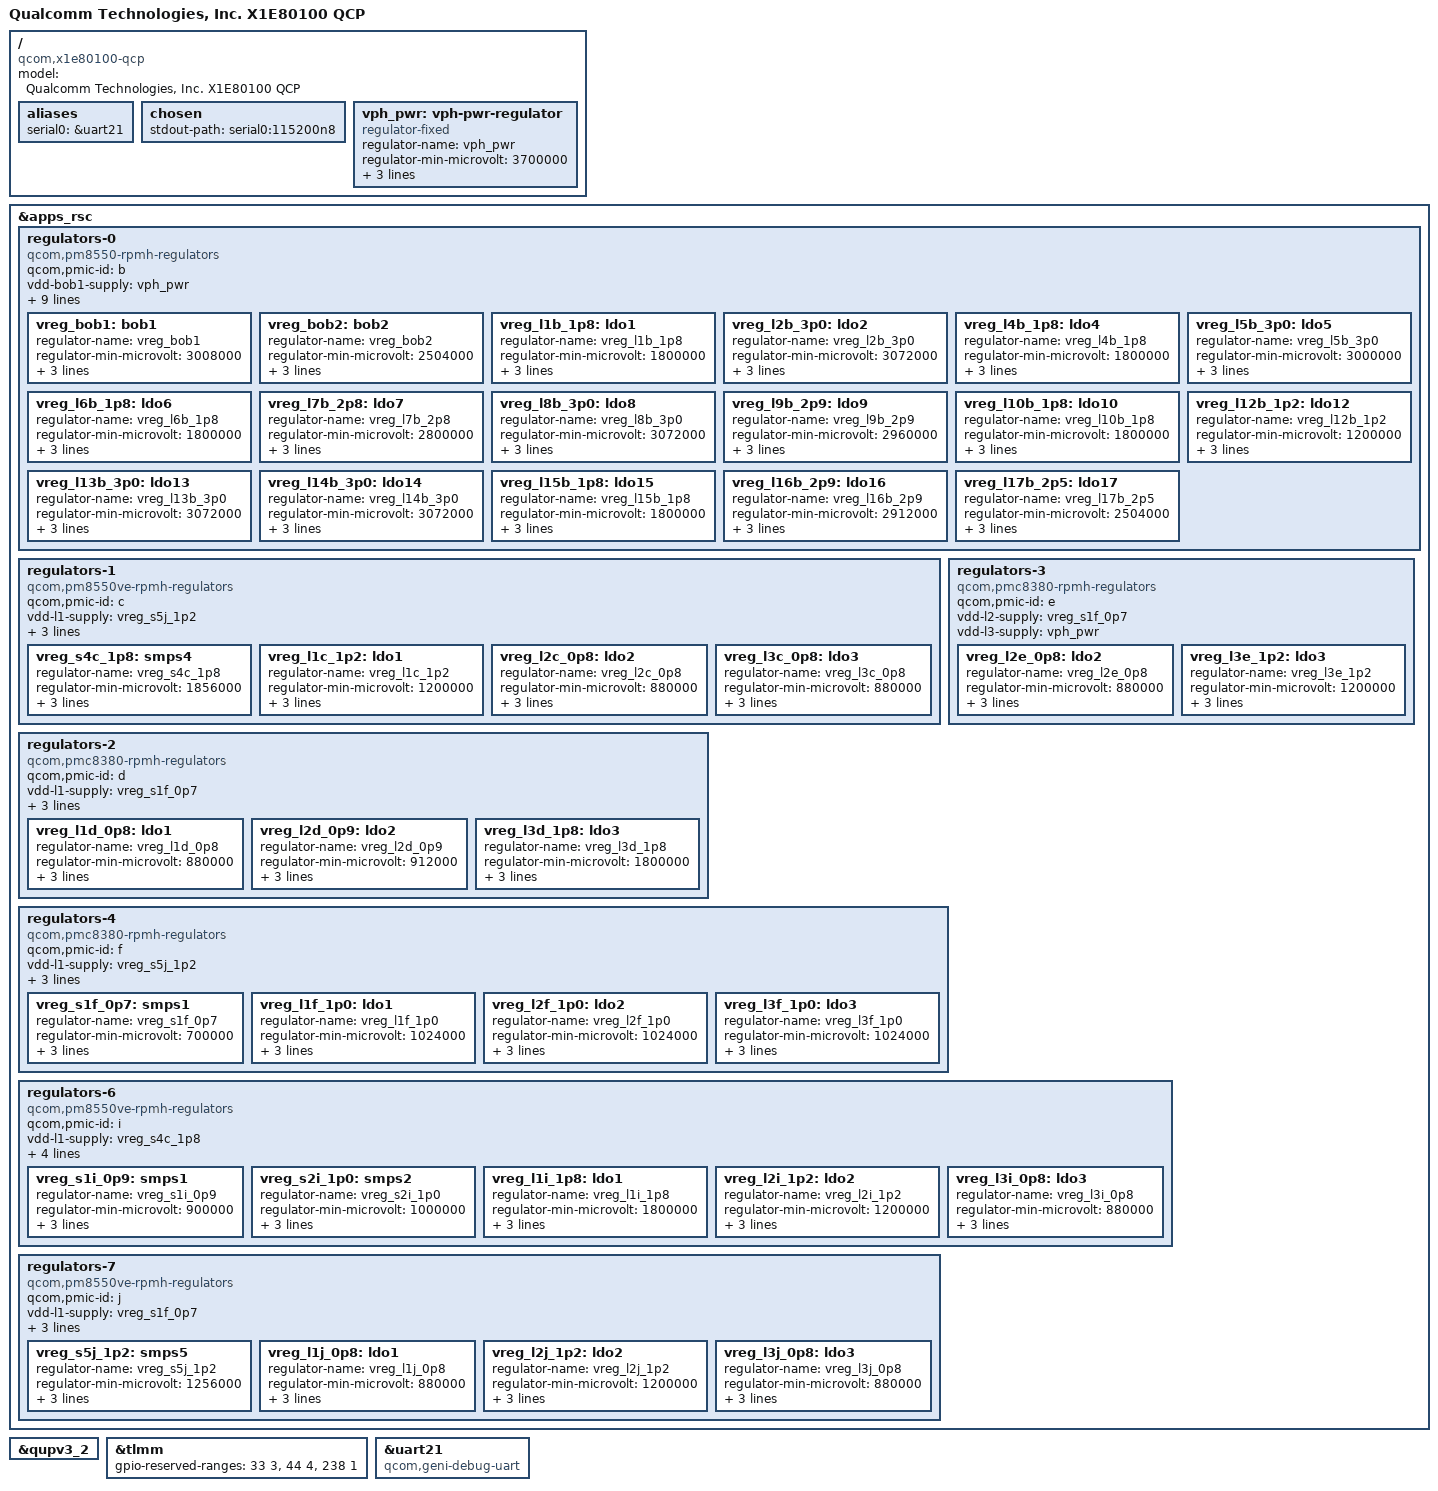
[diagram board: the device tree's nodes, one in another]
// SPDX-License-Identifier: BSD-3-Clause
/*
 * Copyright (c) 2023 Qualcomm Innovation Center, Inc. All rights reserved.
 */

/dts-v1/;

#include <dt-bindings/regulator/qcom,rpmh-regulator.h>

#include "x1e80100.dtsi"

/ {
	model = "Qualcomm Technologies, Inc. X1E80100 QCP";
	compatible = "qcom,x1e80100-qcp", "qcom,x1e80100";

	aliases {
		serial0 = &uart21;
	};

	chosen {
		stdout-path = "serial0:115200n8";
	};

	vph_pwr: vph-pwr-regulator {
		compatible = "regulator-fixed";

		regulator-name = "vph_pwr";
		regulator-min-microvolt = <3700000>;
		regulator-max-microvolt = <3700000>;

		regulator-always-on;
		regulator-boot-on;
	};
};

&apps_rsc {
	regulators-0 {
		compatible = "qcom,pm8550-rpmh-regulators";
		qcom,pmic-id = "b";

		vdd-bob1-supply = <&vph_pwr>;
		vdd-bob2-supply = <&vph_pwr>;
		vdd-l1-l4-l10-supply = <&vreg_s4c_1p8>;
		vdd-l2-l13-l14-supply = <&vreg_bob1>;
		vdd-l5-l16-supply = <&vreg_bob1>;
		vdd-l6-l7-supply = <&vreg_bob2>;
		vdd-l8-l9-supply = <&vreg_bob1>;
		vdd-l12-supply = <&vreg_s5j_1p2>;
		vdd-l15-supply = <&vreg_s4c_1p8>;
		vdd-l17-supply = <&vreg_bob2>;

		vreg_bob1: bob1 {
			regulator-name = "vreg_bob1";
			regulator-min-microvolt = <3008000>;
			regulator-max-microvolt = <3960000>;
			regulator-initial-mode = <RPMH_REGULATOR_MODE_HPM>;
		};

		vreg_bob2: bob2 {
			regulator-name = "vreg_bob2";
			regulator-min-microvolt = <2504000>;
			regulator-max-microvolt = <3008000>;
			regulator-initial-mode = <RPMH_REGULATOR_MODE_HPM>;
		};

		vreg_l1b_1p8: ldo1 {
			regulator-name = "vreg_l1b_1p8";
			regulator-min-microvolt = <1800000>;
			regulator-max-microvolt = <1800000>;
			regulator-initial-mode = <RPMH_REGULATOR_MODE_HPM>;
		};

		vreg_l2b_3p0: ldo2 {
			regulator-name = "vreg_l2b_3p0";
			regulator-min-microvolt = <3072000>;
			regulator-max-microvolt = <3100000>;
			regulator-initial-mode = <RPMH_REGULATOR_MODE_HPM>;
		};

		vreg_l4b_1p8: ldo4 {
			regulator-name = "vreg_l4b_1p8";
			regulator-min-microvolt = <1800000>;
			regulator-max-microvolt = <1800000>;
			regulator-initial-mode = <RPMH_REGULATOR_MODE_HPM>;
		};

		vreg_l5b_3p0: ldo5 {
			regulator-name = "vreg_l5b_3p0";
			regulator-min-microvolt = <3000000>;
			regulator-max-microvolt = <3000000>;
			regulator-initial-mode = <RPMH_REGULATOR_MODE_HPM>;
		};

		vreg_l6b_1p8: ldo6 {
			regulator-name = "vreg_l6b_1p8";
			regulator-min-microvolt = <1800000>;
			regulator-max-microvolt = <2960000>;
			regulator-initial-mode = <RPMH_REGULATOR_MODE_HPM>;
		};

		vreg_l7b_2p8: ldo7 {
			regulator-name = "vreg_l7b_2p8";
			regulator-min-microvolt = <2800000>;
			regulator-max-microvolt = <2800000>;
			regulator-initial-mode = <RPMH_REGULATOR_MODE_HPM>;
		};

		vreg_l8b_3p0: ldo8 {
			regulator-name = "vreg_l8b_3p0";
			regulator-min-microvolt = <3072000>;
			regulator-max-microvolt = <3072000>;
			regulator-initial-mode = <RPMH_REGULATOR_MODE_HPM>;
		};

		vreg_l9b_2p9: ldo9 {
			regulator-name = "vreg_l9b_2p9";
			regulator-min-microvolt = <2960000>;
			regulator-max-microvolt = <2960000>;
			regulator-initial-mode = <RPMH_REGULATOR_MODE_HPM>;
		};

		vreg_l10b_1p8: ldo10 {
			regulator-name = "vreg_l10b_1p8";
			regulator-min-microvolt = <1800000>;
			regulator-max-microvolt = <1800000>;
			regulator-initial-mode = <RPMH_REGULATOR_MODE_HPM>;
		};

		vreg_l12b_1p2: ldo12 {
			regulator-name = "vreg_l12b_1p2";
			regulator-min-microvolt = <1200000>;
			regulator-max-microvolt = <1200000>;
			regulator-initial-mode = <RPMH_REGULATOR_MODE_HPM>;
		};

		vreg_l13b_3p0: ldo13 {
			regulator-name = "vreg_l13b_3p0";
			regulator-min-microvolt = <3072000>;
			regulator-max-microvolt = <3100000>;
			regulator-initial-mode = <RPMH_REGULATOR_MODE_HPM>;
		};

		vreg_l14b_3p0: ldo14 {
			regulator-name = "vreg_l14b_3p0";
			regulator-min-microvolt = <3072000>;
			regulator-max-microvolt = <3072000>;
			regulator-initial-mode = <RPMH_REGULATOR_MODE_HPM>;
		};

		vreg_l15b_1p8: ldo15 {
			regulator-name = "vreg_l15b_1p8";
			regulator-min-microvolt = <1800000>;
			regulator-max-microvolt = <1800000>;
			regulator-initial-mode = <RPMH_REGULATOR_MODE_HPM>;
		};

		vreg_l16b_2p9: ldo16 {
			regulator-name = "vreg_l16b_2p9";
			regulator-min-microvolt = <2912000>;
			regulator-max-microvolt = <2912000>;
			regulator-initial-mode = <RPMH_REGULATOR_MODE_HPM>;
		};

		vreg_l17b_2p5: ldo17 {
			regulator-name = "vreg_l17b_2p5";
			regulator-min-microvolt = <2504000>;
			regulator-max-microvolt = <2504000>;
			regulator-initial-mode = <RPMH_REGULATOR_MODE_HPM>;
		};
	};

	regulators-1 {
		compatible = "qcom,pm8550ve-rpmh-regulators";
		qcom,pmic-id = "c";

		vdd-l1-supply = <&vreg_s5j_1p2>;
		vdd-l2-supply = <&vreg_s1f_0p7>;
		vdd-l3-supply = <&vreg_s1f_0p7>;
		vdd-s4-supply = <&vph_pwr>;

		vreg_s4c_1p8: smps4 {
			regulator-name = "vreg_s4c_1p8";
			regulator-min-microvolt = <1856000>;
			regulator-max-microvolt = <2000000>;
			regulator-initial-mode = <RPMH_REGULATOR_MODE_HPM>;
		};

		vreg_l1c_1p2: ldo1 {
			regulator-name = "vreg_l1c_1p2";
			regulator-min-microvolt = <1200000>;
			regulator-max-microvolt = <1200000>;
			regulator-initial-mode = <RPMH_REGULATOR_MODE_HPM>;
		};

		vreg_l2c_0p8: ldo2 {
			regulator-name = "vreg_l2c_0p8";
			regulator-min-microvolt = <880000>;
			regulator-max-microvolt = <920000>;
			regulator-initial-mode = <RPMH_REGULATOR_MODE_HPM>;
		};

		vreg_l3c_0p8: ldo3 {
			regulator-name = "vreg_l3c_0p8";
			regulator-min-microvolt = <880000>;
			regulator-max-microvolt = <920000>;
			regulator-initial-mode = <RPMH_REGULATOR_MODE_HPM>;
		};
	};

	regulators-2 {
		compatible = "qcom,pmc8380-rpmh-regulators";
		qcom,pmic-id = "d";

		vdd-l1-supply = <&vreg_s1f_0p7>;
		vdd-l2-supply = <&vreg_s1f_0p7>;
		vdd-l3-supply = <&vreg_s4c_1p8>;
		vdd-s1-supply = <&vph_pwr>;

		vreg_l1d_0p8: ldo1 {
			regulator-name = "vreg_l1d_0p8";
			regulator-min-microvolt = <880000>;
			regulator-max-microvolt = <920000>;
			regulator-initial-mode = <RPMH_REGULATOR_MODE_HPM>;
		};

		vreg_l2d_0p9: ldo2 {
			regulator-name = "vreg_l2d_0p9";
			regulator-min-microvolt = <912000>;
			regulator-max-microvolt = <920000>;
			regulator-initial-mode = <RPMH_REGULATOR_MODE_HPM>;
		};

		vreg_l3d_1p8: ldo3 {
			regulator-name = "vreg_l3d_1p8";
			regulator-min-microvolt = <1800000>;
			regulator-max-microvolt = <1800000>;
			regulator-initial-mode = <RPMH_REGULATOR_MODE_HPM>;
		};
	};

	regulators-3 {
		compatible = "qcom,pmc8380-rpmh-regulators";
		qcom,pmic-id = "e";

		vdd-l2-supply = <&vreg_s1f_0p7>;
		vdd-l3-supply = <&vph_pwr>;

		vreg_l2e_0p8: ldo2 {
			regulator-name = "vreg_l2e_0p8";
			regulator-min-microvolt = <880000>;
			regulator-max-microvolt = <920000>;
			regulator-initial-mode = <RPMH_REGULATOR_MODE_HPM>;
		};

		vreg_l3e_1p2: ldo3 {
			regulator-name = "vreg_l3e_1p2";
			regulator-min-microvolt = <1200000>;
			regulator-max-microvolt = <1200000>;
			regulator-initial-mode = <RPMH_REGULATOR_MODE_HPM>;
		};
	};

	regulators-4 {
		compatible = "qcom,pmc8380-rpmh-regulators";
		qcom,pmic-id = "f";

		vdd-l1-supply = <&vreg_s5j_1p2>;
		vdd-l2-supply = <&vreg_s5j_1p2>;
		vdd-l3-supply = <&vreg_s5j_1p2>;
		vdd-s1-supply = <&vph_pwr>;

		vreg_s1f_0p7: smps1 {
			regulator-name = "vreg_s1f_0p7";
			regulator-min-microvolt = <700000>;
			regulator-max-microvolt = <1100000>;
			regulator-initial-mode = <RPMH_REGULATOR_MODE_HPM>;
		};

		vreg_l1f_1p0: ldo1 {
			regulator-name = "vreg_l1f_1p0";
			regulator-min-microvolt = <1024000>;
			regulator-max-microvolt = <1024000>;
			regulator-initial-mode = <RPMH_REGULATOR_MODE_HPM>;
		};

		vreg_l2f_1p0: ldo2 {
			regulator-name = "vreg_l2f_1p0";
			regulator-min-microvolt = <1024000>;
			regulator-max-microvolt = <1024000>;
			regulator-initial-mode = <RPMH_REGULATOR_MODE_HPM>;
		};

		vreg_l3f_1p0: ldo3 {
			regulator-name = "vreg_l3f_1p0";
			regulator-min-microvolt = <1024000>;
			regulator-max-microvolt = <1024000>;
			regulator-initial-mode = <RPMH_REGULATOR_MODE_HPM>;
		};
	};

	regulators-6 {
		compatible = "qcom,pm8550ve-rpmh-regulators";
		qcom,pmic-id = "i";

		vdd-l1-supply = <&vreg_s4c_1p8>;
		vdd-l2-supply = <&vreg_s5j_1p2>;
		vdd-l3-supply = <&vreg_s1f_0p7>;
		vdd-s1-supply = <&vph_pwr>;
		vdd-s2-supply = <&vph_pwr>;

		vreg_s1i_0p9: smps1 {
			regulator-name = "vreg_s1i_0p9";
			regulator-min-microvolt = <900000>;
			regulator-max-microvolt = <920000>;
			regulator-initial-mode = <RPMH_REGULATOR_MODE_HPM>;
		};

		vreg_s2i_1p0: smps2 {
			regulator-name = "vreg_s2i_1p0";
			regulator-min-microvolt = <1000000>;
			regulator-max-microvolt = <1100000>;
			regulator-initial-mode = <RPMH_REGULATOR_MODE_HPM>;
		};

		vreg_l1i_1p8: ldo1 {
			regulator-name = "vreg_l1i_1p8";
			regulator-min-microvolt = <1800000>;
			regulator-max-microvolt = <1800000>;
			regulator-initial-mode = <RPMH_REGULATOR_MODE_HPM>;
		};

		vreg_l2i_1p2: ldo2 {
			regulator-name = "vreg_l2i_1p2";
			regulator-min-microvolt = <1200000>;
			regulator-max-microvolt = <1200000>;
			regulator-initial-mode = <RPMH_REGULATOR_MODE_HPM>;
		};

		vreg_l3i_0p8: ldo3 {
			regulator-name = "vreg_l3i_0p8";
			regulator-min-microvolt = <880000>;
			regulator-max-microvolt = <920000>;
			regulator-initial-mode = <RPMH_REGULATOR_MODE_HPM>;
		};
	};

	regulators-7 {
		compatible = "qcom,pm8550ve-rpmh-regulators";
		qcom,pmic-id = "j";

		vdd-l1-supply = <&vreg_s1f_0p7>;
		vdd-l2-supply = <&vph_pwr>;
		vdd-l3-supply = <&vreg_s1f_0p7>;
		vdd-s5-supply = <&vph_pwr>;

		vreg_s5j_1p2: smps5 {
			regulator-name = "vreg_s5j_1p2";
			regulator-min-microvolt = <1256000>;
			regulator-max-microvolt = <1304000>;
			regulator-initial-mode = <RPMH_REGULATOR_MODE_HPM>;
		};

		vreg_l1j_0p8: ldo1 {
			regulator-name = "vreg_l1j_0p8";
			regulator-min-microvolt = <880000>;
			regulator-max-microvolt = <920000>;
			regulator-initial-mode = <RPMH_REGULATOR_MODE_HPM>;
		};

		vreg_l2j_1p2: ldo2 {
			regulator-name = "vreg_l2j_1p2";
			regulator-min-microvolt = <1200000>;
			regulator-max-microvolt = <1200000>;
			regulator-initial-mode = <RPMH_REGULATOR_MODE_HPM>;
		};

		vreg_l3j_0p8: ldo3 {
			regulator-name = "vreg_l3j_0p8";
			regulator-min-microvolt = <880000>;
			regulator-max-microvolt = <920000>;
			regulator-initial-mode = <RPMH_REGULATOR_MODE_HPM>;
		};
	};
};

&qupv3_2 {
	status = "okay";
};

&tlmm {
	gpio-reserved-ranges = <33 3>, /* Unused */
			       <44 4>, /* SPI (TPM) */
			       <238 1>; /* UFS Reset */
};

&uart21 {
	compatible = "qcom,geni-debug-uart";
	status = "okay";
};
